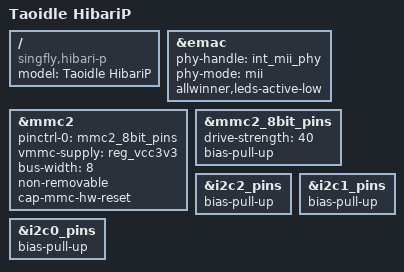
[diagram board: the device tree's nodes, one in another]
#include "sun8i-h3-card-core.dtsi"

/ {
	model = "Taoidle HibariP";
	compatible = "singfly,hibari-p", "allwinner,sun8i-h3";
};

&emac {
	phy-handle = <&int_mii_phy>;
	phy-mode = "mii";
	allwinner,leds-active-low;
	status = "okay";
};

&mmc2 {
	pinctrl-names = "default";
	pinctrl-0 = <&mmc2_8bit_pins>;
	vmmc-supply = <&reg_vcc3v3>;
	bus-width = <8>;
	non-removable;
	cap-mmc-hw-reset;
	status = "okay";
};

&mmc2_8bit_pins {
	/* Increase drive strength for DDR modes */
	drive-strength = <40>;
	/* eMMC is missing pull-ups */
	bias-pull-up;
};


&i2c2_pins {
   bias-pull-up;
};

&i2c1_pins {
   bias-pull-up;
};

&i2c0_pins {
   bias-pull-up;
};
